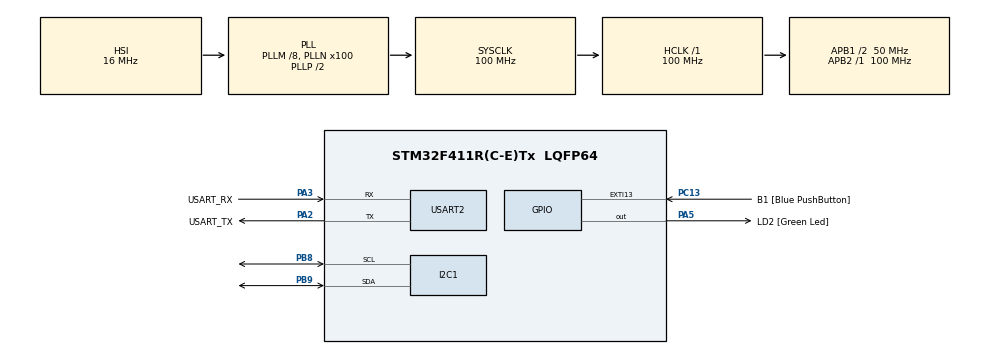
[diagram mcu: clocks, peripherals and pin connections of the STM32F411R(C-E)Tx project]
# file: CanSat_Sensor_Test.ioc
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Mcu.Family=STM32F4
Mcu.Name=STM32F411R(C-E)Tx
Mcu.Package=LQFP64
NVIC.PriorityGroup=NVIC_PRIORITYGROUP_0
PA13.GPIO_Label=TMS
PA13.Mode=Serial_Wire
PA13.Signal=SYS_JTMS-SWDIO
PA14.GPIO_Label=TCK
PA14.Mode=Serial_Wire
PA14.Signal=SYS_JTCK-SWCLK
PA2.GPIO_Label=USART_TX
PA2.Mode=Asynchronous
PA2.Signal=USART2_TX
PA3.GPIO_Label=USART_RX
PA3.Mode=Asynchronous
PA3.Signal=USART2_RX
PA5.GPIO_Label=LD2 [Green Led]
PA5.Signal=GPIO_Output
PB3.GPIO_Label=SWO
PB3.Signal=SYS_JTDO-SWO
PB8.Mode=I2C
PB8.Signal=I2C1_SCL
PB9.Mode=I2C
PB9.Signal=I2C1_SDA
PC13-ANTI_TAMP.GPIO_Label=B1 [Blue PushButton]
PC13-ANTI_TAMP.GPIO_ModeDefaultEXTI=GPIO_MODE_IT_FALLING
PC13-ANTI_TAMP.Signal=GPXTI13
PC14-OSC32_IN.Mode=LSE-External-Oscillator
PC14-OSC32_IN.Signal=RCC_OSC32_IN
PC15-OSC32_OUT.Mode=LSE-External-Oscillator
PC15-OSC32_OUT.Signal=RCC_OSC32_OUT
PH0\ -\ OSC_IN.Mode=HSE-External-Clock-Source
PH0\ -\ OSC_IN.Signal=RCC_OSC_IN
PH1\ -\ OSC_OUT.Mode=HSE-External-Clock-Source
PH1\ -\ OSC_OUT.Signal=RCC_OSC_OUT
ProjectManager.HeapSize=0x200
ProjectManager.StackSize=0x400
ProjectManager.TargetToolchain=STM32CubeIDE
RCC.48MHZClocksFreq_Value=50000000
RCC.AHBFreq_Value=100000000
RCC.APB1CLKDivider=RCC_HCLK_DIV2
RCC.APB1Freq_Value=50000000
RCC.APB1TimFreq_Value=100000000
RCC.APB2Freq_Value=100000000
RCC.APB2TimFreq_Value=100000000
RCC.CortexFreq_Value=100000000
RCC.FLatency-AdvancedSettings=FLASH_LATENCY_3
RCC.HCLKFreq_Value=100000000
RCC.HSE_VALUE=8000000
RCC.HSI_VALUE=16000000
RCC.PLLM=8
RCC.PLLN=100
RCC.SYSCLKFreq_VALUE=100000000
RCC.SYSCLKSource=RCC_SYSCLKSOURCE_PLLCLK
RCC.VCOOutputFreq_Value=200000000
USART2.VirtualMode=VM_ASYNC
board=NUCLEO-F411RE

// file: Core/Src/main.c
/* USER CODE BEGIN Header */
/**
  ******************************************************************************
  * @file           : main.c
  * @brief          : Main program body
  ******************************************************************************
  * @attention
  *
  * Copyright (c) 2026 STMicroelectronics.
  * All rights reserved.
  *
  * This software is licensed under terms that can be found in the LICENSE file
  * in the root directory of this software component.
  * If no LICENSE file comes with this software, it is provided AS-IS.
  *
  ******************************************************************************
  */
/* USER CODE END Header */
#include "main.h"
#include "i2c.h"
#include "usart.h"
#include "gpio.h"

/* USER CODE BEGIN PV */
/* USER CODE BEGIN PV */
volatile uint8_t i2c_scan_result = 0;
HAL_StatusTypeDef i2c_status;
/* USER CODE END PV */
/* USER CODE END PV */

void SystemClock_Config(void);

int main(void)
{

  /* MCU Configuration--------------------------------------------------------*/

  /* Reset of all peripherals, Initializes the Flash interface and the Systick. */
  HAL_Init();

  /* Configure the system clock */
  SystemClock_Config();

  /* Initialize all configured peripherals */
  MX_GPIO_Init();
  MX_I2C1_Init();
  MX_USART2_UART_Init();
  /* USER CODE BEGIN 2 */
  /* USER CODE BEGIN 2 */
  // Escaneamos las direcciones del bus I2C
  for (uint16_t i = 1; i < 128; i++) {
      // Probamos si el dispositivo responde en la dirección i
      i2c_status = HAL_I2C_IsDeviceReady(&hi2c1, (uint16_t)(i << 1), 3, 5);

      if (i2c_status == HAL_OK) {
          i2c_scan_result = i; // Guardamos la dirección encontrada
          // Si quieres, puedes poner un Breakpoint aquí (doble clic en el borde)
      }
  }
  /* USER CODE END 2 */
  /* USER CODE END 2 */

  /* Infinite loop */
  while (1)
  {

  }
}

void SystemClock_Config(void)
{
  RCC_OscInitTypeDef RCC_OscInitStruct = {0};
  RCC_ClkInitTypeDef RCC_ClkInitStruct = {0};

  /** Configure the main internal regulator output voltage
  */
  __HAL_RCC_PWR_CLK_ENABLE();
  __HAL_PWR_VOLTAGESCALING_CONFIG(PWR_REGULATOR_VOLTAGE_SCALE1);

  /** Initializes the RCC Oscillators according to the specified parameters
  * in the RCC_OscInitTypeDef structure.
  */
  RCC_OscInitStruct.OscillatorType = RCC_OSCILLATORTYPE_HSI;
  RCC_OscInitStruct.HSIState = RCC_HSI_ON;
  RCC_OscInitStruct.HSICalibrationValue = RCC_HSICALIBRATION_DEFAULT;
  RCC_OscInitStruct.PLL.PLLState = RCC_PLL_ON;
  RCC_OscInitStruct.PLL.PLLSource = RCC_PLLSOURCE_HSI;
  RCC_OscInitStruct.PLL.PLLM = 8;
  RCC_OscInitStruct.PLL.PLLN = 100;
  RCC_OscInitStruct.PLL.PLLP = RCC_PLLP_DIV2;
  RCC_OscInitStruct.PLL.PLLQ = 4;
  if (HAL_RCC_OscConfig(&RCC_OscInitStruct) != HAL_OK)
  {
    Error_Handler();
  }

  /** Initializes the CPU, AHB and APB buses clocks
  */
  RCC_ClkInitStruct.ClockType = RCC_CLOCKTYPE_HCLK|RCC_CLOCKTYPE_SYSCLK
                              |RCC_CLOCKTYPE_PCLK1|RCC_CLOCKTYPE_PCLK2;
  RCC_ClkInitStruct.SYSCLKSource = RCC_SYSCLKSOURCE_PLLCLK;
  RCC_ClkInitStruct.AHBCLKDivider = RCC_SYSCLK_DIV1;
  RCC_ClkInitStruct.APB1CLKDivider = RCC_HCLK_DIV2;
  RCC_ClkInitStruct.APB2CLKDivider = RCC_HCLK_DIV1;

  if (HAL_RCC_ClockConfig(&RCC_ClkInitStruct, FLASH_LATENCY_3) != HAL_OK)
  {
    Error_Handler();
  }
}

void Error_Handler(void)
{
  __disable_irq();
  while (1)
  {
  }
}
